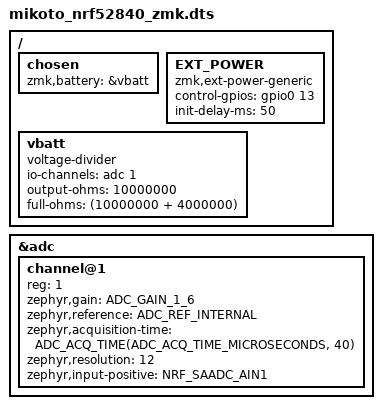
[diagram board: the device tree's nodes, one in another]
/*
 * Copyright (c) 2026 The ZMK Contributors
 *
 * SPDX-License-Identifier: MIT
 */

#include <../boards/zhiayang/mikoto/mikoto.dts>
#include <common/nordic/nrf52840_uf2_boot_mode.dtsi>

/ {
    chosen {
        zmk,battery = &vbatt;
    };

    // Node name must match original "EXT_POWER" label to preserve user settings.
    EXT_POWER {
        compatible = "zmk,ext-power-generic";
        control-gpios = <&gpio0 13 GPIO_ACTIVE_HIGH>;
        init-delay-ms = <50>;
    };

    vbatt: vbatt {
        compatible = "voltage-divider";
        io-channels = <&adc 1>;
        output-ohms = <10000000>;
        full-ohms = <(10000000 + 4000000)>;
    };
};

&adc {
    #address-cells = <1>;
    #size-cells = <0>;
    status = "okay";

    channel@1 {
        reg = <1>;
        zephyr,gain = "ADC_GAIN_1_6";
        zephyr,reference = "ADC_REF_INTERNAL";
        zephyr,acquisition-time = <ADC_ACQ_TIME(ADC_ACQ_TIME_MICROSECONDS, 40)>;
        zephyr,resolution = <12>;
        zephyr,input-positive = <NRF_SAADC_AIN1>;
    };
};
